# ATSAMA5D27WLSOM1 device description
Architecture: CORTEX-A5; Family: SAMA5; Series: SAMA5D2
Registers are 32-bit, read-write, no defined reset value unless marked. A register's access mark holds for its fields unless they carry their own. Offsets are from the block's base; [hi:lo] are bit positions; {n}, {i} and the like mark numbered series.

## SHDWC — Shutdown Controller
Instances: SHDWC 0xF8048010
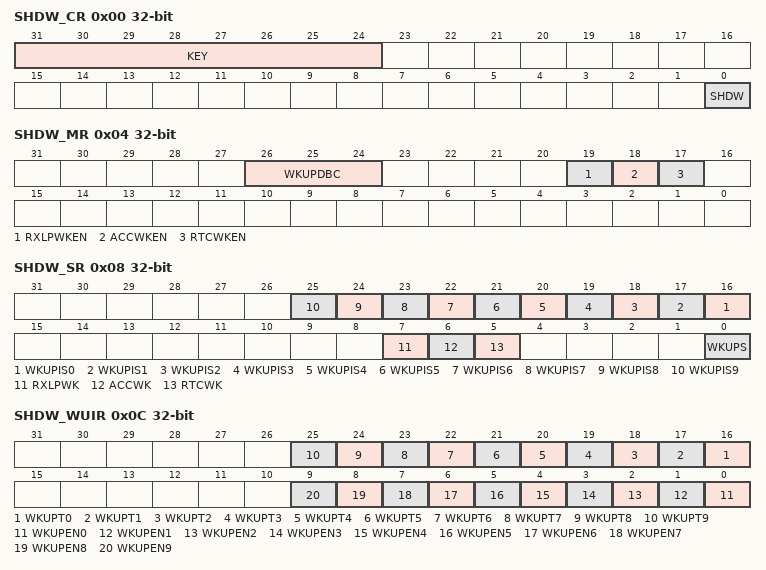
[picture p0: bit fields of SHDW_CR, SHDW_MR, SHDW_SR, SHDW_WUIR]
0x00 SHDW_CR wo — Shutdown Control Register
  [31:24] KEY — Password
    165=PASSWD (Writing any other value in this field aborts the write operation.)
  [0] SHDW — Shutdown Command
0x04 SHDW_MR — Shutdown Mode Register
  [26:24] WKUPDBC — Wake-up Inputs Debouncer Period
    0=IMMEDIATE (Immediate, no debouncing, detected active at least on one Slow Clock edge); 1=_3_SLCK (PIOBUx shall be in its active state for at least 3 SLCK periods); 2=_32_SLCK (PIOBUx shall be in its active state for at least 32 SLCK periods); 3=_512_SLCK (PIOBUx shall be in its active state for at least 512 SLCK periods); 4=_4096_SLCK (PIOBUx shall be in its active state for at least 4,096 SLCK periods); 5=_32768_SLCK (PIOBUx shall be in its active state for at least 32,768 SLCK periods)
  [19] RXLPWKEN — Debug Unit Wake-up Enable
  [18] ACCWKEN — Analog Comparator Controller Wake-up Enable
  [17] RTCWKEN — Real-time Clock Wake-up Enable
0x08 SHDW_SR ro — Shutdown Status Register
  [n+16] WKUPIS{n} (n=0..9) — Wake-up {n} Input Status
    0=DISABLE (The corresponding wake-up input is disabled, or was inactive at the time the debouncer triggered a wake-up event.); 1=ENABLE (The corresponding wake-up input was active at the time the debouncer triggered a wake-up event.)
  [7] RXLPWK — Debug Unit Wake-up
  [6] ACCWK — Analog Comparator Controller Wake-up
  [5] RTCWK
  [0] WKUPS — PIOBU, WKUP Wake-up Status
    0=NO (No wake-up due to the assertion of the PIOBU, WKUP pins has occurred since the last read of SHDW_SR.); 1=PRESENT (At least one wake-up due to the assertion of the PIOBU, WKUP pins has occurred since the last read of SHDW_SR.)
0x0C SHDW_WUIR — Shutdown Wake-up Inputs Register
  [n+16] WKUPT{n} (n=0..9) — Wake-up {n} Input Type
    0=LOW (A falling edge followed by a low level, for a period defined by WKUPDBC, on the corresponding wake-up input forces the wake-up of the core power supply.); 1=HIGH (A rising edge followed by a high level, for a period defined by WKUPDBC, on the corresponding wake-up input forces the wake-up of the core power supply.)
  [n] WKUPEN{n} (n=0..9) — Wake-up {n} Input Enable
    0=DISABLE (The corresponding wake-up input has no wake-up effect.); 1=ENABLE (The corresponding wake-up input forces the wake-up of the core power supply.)

## SYSCWP — System Controller Write Protection
Instances: SYSCWP 0xF8048194
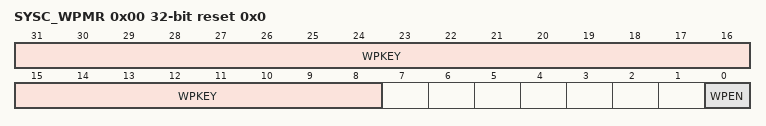
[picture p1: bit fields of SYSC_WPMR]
0x00 SYSC_WPMR reset 0x0 — Write Protection Mode Register
  [31:8] WPKEY — Write Protection Key
    0x535943=PASSWD (Writing any other value in this field aborts the write operation of the WPEN and WPITEN bits. Always reads as 0.)
  [0] WPEN — Write Protection Enable
    0=Disables the write protection of the configuration registers if WPKEY corresponds to 0x535943 (SYC in ASCII); 1=Enables the write protection of the configuration registers if WPKEY corresponds to 0x535943 (SYC in ASCII)

## TDES — Triple Data Encryption Standard
Instances: TDES 0xFC044000
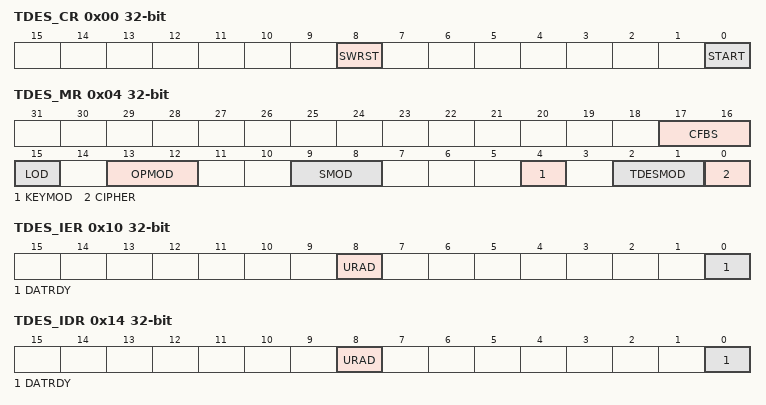
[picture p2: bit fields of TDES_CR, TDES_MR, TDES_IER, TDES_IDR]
0x00 TDES_CR wo — Control Register
  [8] SWRST — Software Reset
  [0] START — Start Processing
0x04 TDES_MR — Mode Register
  [17:16] CFBS — Cipher Feedback Data Size
    0=SIZE_64BIT (64-bit); 1=SIZE_32BIT (32-bit); 2=SIZE_16BIT (16-bit); 3=SIZE_8BIT (8-bit)
  [15] LOD — Last Output Data Mode
  [13:12] OPMOD — Operating Mode
    0=ECB (Electronic Code Book mode); 1=CBC (Cipher Block Chaining mode); 2=OFB (Output Feedback mode); 3=CFB (Cipher Feedback mode)
  [9:8] SMOD — Start Mode
    0=MANUAL_START (Manual Mode); 1=AUTO_START (Auto Mode); 2=IDATAR0_START (TDES_IDATAR0 accesses only Auto Mode)
  [4] KEYMOD — Key Mode
  [2:1] TDESMOD — ALGORITHM Mode
    0=SINGLE_DES (Single DES processing using Key 1 Registers); 1=TRIPLE_DES (Triple DES processing using Key 1, Key 2 and Key 3 Registers); 2=XTEA (XTEA processing using Key 1 and Key 2 Registers)
  [0] CIPHER — Processing Mode
    0=DECRYPT (Decrypts data.); 1=ENCRYPT (Encrypts data.)
0x10 TDES_IER wo — Interrupt Enable Register
  [8] URAD — Unspecified Register Access Detection Interrupt Enable
  [0] DATRDY — Data Ready Interrupt Enable
0x14 TDES_IDR wo — Interrupt Disable Register
  [8] URAD — Unspecified Register Access Detection Interrupt Disable
  [0] DATRDY — Data Ready Interrupt Disable
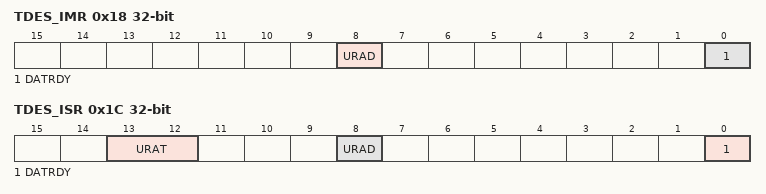
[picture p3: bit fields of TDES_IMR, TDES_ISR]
0x18 TDES_IMR ro — Interrupt Mask Register
  [8] URAD — Unspecified Register Access Detection Interrupt Mask
  [0] DATRDY — Data Ready Interrupt Mask
0x1C TDES_ISR ro — Interrupt Status Register
  [13:12] URAT — Unspecified Register Access (cleared by setting bit TDES_CR.SWRST)
    0=IDR_WR_PROCESSING (Input Data Register written during data processing when SMOD = 0x2 mode.); 1=ODR_RD_PROCESSING (Output Data Register read during data processing.); 2=MR_WR_PROCESSING (Mode Register written during data processing.); 3=WOR_RD_ACCESS (Write-only register read access.)
  [8] URAD — Unspecified Register Access Detection Status (cleared by setting bit TDES_CR.SWRST)
  [0] DATRDY — Data Ready (cleared by setting bit START or bit SWRST in TDES_CR or by reading TDES_ODATARx)
{0x20+4i} TDES_KEY1WR[{i}] (i=0..1) wo — Key 1 Word Register
  [31:0] KEY1W — Key 1 Word
{0x28+4i} TDES_KEY2WR[{i}] (i=0..1) wo — Key 2 Word Register
  [31:0] KEY2W — Key 2 Word
{0x30+4i} TDES_KEY3WR[{i}] (i=0..1) wo — Key 3 Word Register
  [31:0] KEY3W — Key 3 Word
{0x40+4i} TDES_IDATAR[{i}] (i=0..1) wo — Input Data Register
  [31:0] IDATA — Input Data
{0x50+4i} TDES_ODATAR[{i}] (i=0..1) ro — Output Data Register
  [31:0] ODATA — Output Data
{0x60+4i} TDES_IVR[{i}] (i=0..1) wo — Initialization Vector Register
  [31:0] IV — Initialization Vector
0x70 TDES_XTEA_RNDR — XTEA Rounds Register
  [5:0] XTEA_RNDS — Number of Rounds
